VERSION ""

NS_ :

BS_:

BU_:

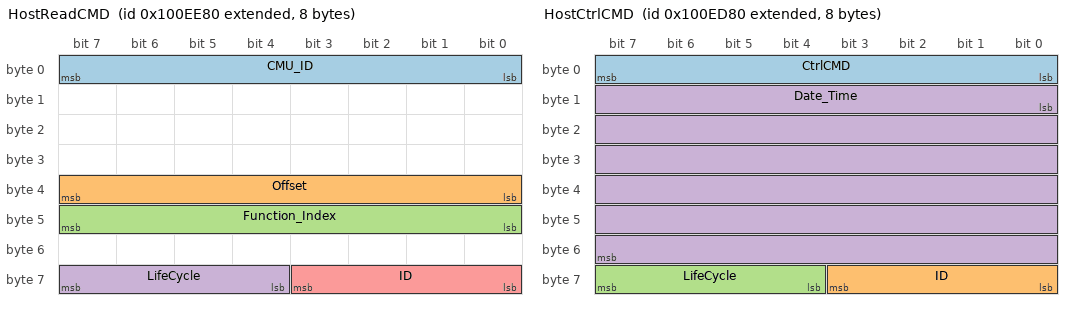
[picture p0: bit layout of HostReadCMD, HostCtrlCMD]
BO_ 2164321920 HostReadCMD: 8 Vector__XXX
 SG_ CMU_ID : 0|8@1+ (1,0) [0|0] "" Vector__XXX
 SG_ Offset : 32|8@1+ (1,0) [0|0] "" Vector__XXX
 SG_ Function_Index : 40|8@1+ (1,0) [0|0] "" Vector__XXX
 SG_ LifeCycle : 60|4@1+ (1,0) [0|0] "" Vector__XXX
 SG_ ID : 56|4@1+ (1,0) [0|0] "" Vector__XXX

BO_ 2164321664 HostCtrlCMD: 8 Vector__XXX
 SG_ CtrlCMD : 0|8@1+ (1,0) [0|0] "" Vector__XXX
 SG_ ID : 56|4@1+ (1,0) [0|0] "" Vector__XXX
 SG_ LifeCycle : 60|4@1+ (1,0) [0|0] "" Vector__XXX
 SG_ Date_Time : 8|48@1+ (1,0) [0|0] "" Vector__XXX
